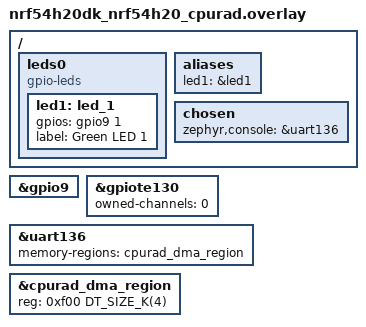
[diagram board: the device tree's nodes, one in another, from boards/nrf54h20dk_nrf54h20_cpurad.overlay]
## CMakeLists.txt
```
#
# Copyright (c) 2024 Nordic Semiconductor
#
# SPDX-License-Identifier: LicenseRef-Nordic-5-Clause
#

cmake_minimum_required(VERSION 3.20.0)
find_package(Zephyr REQUIRED HINTS $ENV{ZEPHYR_BASE})
project(iso_time_sync)

target_include_directories(app PRIVATE include)
target_sources(app PRIVATE src/main.c src/timed_led_toggle.c)

if (CONFIG_BT_CENTRAL)
    target_sources(app PRIVATE src/central.c)
endif()

if (CONFIG_BT_PERIPHERAL)
    target_sources(app PRIVATE src/peripheral.c)
endif()

if (CONFIG_SOC_COMPATIBLE_NRF52X)
    target_sources(app PRIVATE src/controller_time_nrf52.c)
elseif (CONFIG_SOC_COMPATIBLE_NRF5340_CPUAPP)
    target_sources(app PRIVATE src/controller_time_nrf53_app.c)
elseif (CONFIG_SOC_SERIES_NRF54LX)
    target_sources(app PRIVATE src/controller_time_nrf54l.c)
elseif (CONFIG_SOC_SERIES_NRF54HX)
    target_sources(app PRIVATE src/controller_time_nrf54h.c)
else()
    MESSAGE(FATAL_ERROR "Unsupported series")
endif()
```

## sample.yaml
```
sample:
  description: Bluetooth Connection time synchronization sample
  name: Bluetooth Connection time synchronization
tests:
  sample.bluetooth.conn_time_sync:
    sysbuild: true
    build_only: true
    integration_platforms:
      - nrf52840dk/nrf52840
      - nrf52833dk/nrf52833
      - nrf5340dk/nrf5340/cpuapp
      - nrf54l15dk/nrf54l15/cpuapp
      - nrf54l15pdk/nrf54l15/cpuapp
      - nrf54h20dk/nrf54h20/cpuapp
      - nrf54h20dk/nrf54h20/cpurad
    platform_allow:
      - nrf52840dk/nrf52840
      - nrf52833dk/nrf52833
      - nrf5340dk/nrf5340/cpuapp
      - nrf54l15dk/nrf54l15/cpuapp
      - nrf54l15pdk/nrf54l15/cpuapp
      - nrf54h20dk/nrf54h20/cpuapp
      - nrf54h20dk/nrf54h20/cpurad
    tags: bluetooth ci_build sysbuild
```

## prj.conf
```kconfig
#
# Copyright (c) 2024 Nordic Semiconductor
#
# SPDX-License-Identifier: LicenseRef-Nordic-5-Clause
#

CONFIG_NCS_SAMPLES_DEFAULTS=y

CONFIG_BT_DEVICE_NAME="Conn time sync"
CONFIG_BT=y
CONFIG_BT_PERIPHERAL=y
CONFIG_BT_CENTRAL=y
CONFIG_BT_MAX_CONN=3
CONFIG_BT_CTLR_SDC_PERIPHERAL_COUNT=1

CONFIG_BT_GATT_CLIENT=y

CONFIG_CONSOLE=y
CONFIG_CONSOLE_SUBSYS=y
CONFIG_CONSOLE_HANDLER=y
CONFIG_CONSOLE_GETCHAR=y

CONFIG_BT_CTLR_SDC_CONN_ANCHOR_POINT_REPORT=y
CONFIG_BT_HCI_VS_EVT_USER=y
# CONFIG_NRF_REGTOOL_VERBOSITY=3
```

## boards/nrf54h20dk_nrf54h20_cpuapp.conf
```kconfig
CONFIG_GPIO=y
CONFIG_NRFX_DPPI=y
CONFIG_BT_RX_STACK_SIZE=2048
```

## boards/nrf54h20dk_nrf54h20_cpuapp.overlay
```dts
/*
 * Copyright (c) 2023 Nordic Semiconductor ASA
 *
 * SPDX-License-Identifier: LicenseRef-Nordic-5-Clause
 */

 //overlay stuff needs to get fixed first!
    &{/leds/led_1} {
	label = "led1a";  // Keeping the original as is
    };

//     &{/leds0/led_1} {
// 	label = "led1a";  // Renaming to a unique identifier
//     };

 / {
	leds0 {
	    compatible = "gpio-leds";
	    led1: led_1 {
		gpios = <&gpio9 1 GPIO_ACTIVE_HIGH>;
		label = "Green LED 1";
	    };
	};

	aliases {
	    led1 = &led1;
	};

	chosen {
	    zephyr,console = &uart136;
	};
    };

    &gpio9 {
	status = "okay";
    };

    &gpiote130 {
	owned-channels = <0>;
	status = "okay";
    };

// // temp fix to compile for radio core:
//     &uart136 {
// 	status = "okay";
// 	memory-regions = <&cpurad_dma_region>;
//     };

//     &cpuapp_dma_region {
// 	    reg = <0xe80 0x80>;
//     };

//     &cpurad_dma_region {
// 	reg = <0xf00 DT_SIZE_K(4)>;
//     };

//     DPPIC020 for the Radio Core and DPPIC030 for peripheral interactions
//     &dppic020 {
// 	status = "okay";
// 	// source-channels = < 0 1 >;
// 	// sink-channels = < 2 3 >;
// 	source-channels = <0 1 2 3 4 5>;
// 	sink-channels = <6 7 8 9 10 11>;
//     };
```

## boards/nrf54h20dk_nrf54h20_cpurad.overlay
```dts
/*
 * Copyright (c) 2023 Nordic Semiconductor ASA
 *
 * SPDX-License-Identifier: LicenseRef-Nordic-5-Clause
 */

 / {
	leds0 {
	    compatible = "gpio-leds";
	    led1: led_1 {
		gpios = <&gpio9 1 GPIO_ACTIVE_HIGH>;
		label = "Green LED 1";
	    };
	};

	aliases {
	    led1 = &led1;
	};

	chosen {
	    zephyr,console = &uart136;
	};
    };

    &gpio9 {
	status = "okay";
    };

    &gpiote130 {
	owned-channels = <0>;
	status = "okay";
    };

// temp fix to compile for radio core:
    &uart136 {
	status = "okay";
	memory-regions = <&cpurad_dma_region>;
    };

    &cpurad_dma_region {
	reg = <0xf00 DT_SIZE_K(4)>;
    };
```

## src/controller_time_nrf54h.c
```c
/*
 * Copyright (c) 2024 Nordic Semiconductor ASA
 *
 * SPDX-License-Identifier: LicenseRef-Nordic-5-Clause
 */

/** This file implements controller time management for 54 Series devices
 */

#include <zephyr/kernel.h>
#include <nrfx_grtc.h>
#include "conn_time_sync.h"

static uint8_t grtc_channel;

int controller_time_init(void)
{
	int ret;

	ret = nrfx_grtc_channel_alloc(&grtc_channel);
	if (ret != NRFX_SUCCESS) {
		printk("Failed allocating GRTC channel (ret: %d)\n", ret - NRFX_ERROR_BASE_NUM);
		return -ENODEV;
	}

	nrf_grtc_sys_counter_compare_event_enable(NRF_GRTC, grtc_channel);

	return 0;
}

uint64_t controller_time_us_get(void)
{
	int ret;
	uint64_t current_time_us;

	ret = nrfx_grtc_syscounter_get(&current_time_us);
	if (ret != NRFX_SUCCESS) {
		printk("Failed obtaining system time (ret: %d)\n", ret - NRFX_ERROR_BASE_NUM);
		return 0;
	}

	return current_time_us;
}

void controller_time_trigger_set(uint64_t timestamp_us)
{
	int ret;

	nrfx_grtc_channel_t chan_data = {
		.channel = grtc_channel,
	};

	ret = nrfx_grtc_syscounter_cc_absolute_set(&chan_data, timestamp_us, false);
	if (ret != NRFX_SUCCESS) {
		printk("Failed setting CC (ret: %d)\n", ret - NRFX_ERROR_BASE_NUM);
	}
}

uint32_t controller_time_trigger_event_addr_get(void)
{
	return nrf_grtc_event_address_get(NRF_GRTC,
					  nrf_grtc_sys_counter_compare_event_get(grtc_channel));
}

SYS_INIT(controller_time_init, POST_KERNEL, CONFIG_KERNEL_INIT_PRIORITY_DEFAULT);
```

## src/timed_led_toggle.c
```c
/*
 * Copyright (c) 2024 Nordic Semiconductor ASA
 *
 * SPDX-License-Identifier: LicenseRef-Nordic-5-Clause
 */

/** This file implements timed toggling a LED
 *
 * To achieve accurate toggling, it interacts with the controller
 * clock using PPI.
 */

#include <zephyr/kernel.h>
#include <zephyr/device.h>
#include <zephyr/drivers/gpio.h>
#include <soc.h>
#include <hal/nrf_rtc.h>
#include <nrfx_gpiote.h>
#include <helpers/nrfx_gppi.h>
#include "conn_time_sync.h"

#define GPIOTE_INST NRF_DT_GPIOTE_INST(DT_ALIAS(led1), gpios)
#define GPIOTE_NODE DT_NODELABEL(_CONCAT(gpiote, GPIOTE_INST))

BUILD_ASSERT(IS_ENABLED(_CONCAT(CONFIG_, _CONCAT(NRFX_GPIOTE, GPIOTE_INST))),
	     "NRFX_GPIOTE" STRINGIFY(GPIOTE_INST) " must be enabled in Kconfig");

static const nrfx_gpiote_t gpiote = NRFX_GPIOTE_INSTANCE(GPIOTE_INST);
static struct gpio_dt_spec led = GPIO_DT_SPEC_GET_OR(DT_ALIAS(led1), gpios, {0});

static uint8_t previous_led_value;

struct gpio_nrfx_cfg {
	/* gpio_driver_config needs to be first */
	struct gpio_driver_config common;
	NRF_GPIO_Type *port;
	uint32_t edge_sense;
	uint8_t port_num;
	nrfx_gpiote_t gpiote;
};

int timed_led_toggle_init(void)
{
	int err;
	uint8_t ppi_chan_led_toggle;
	uint8_t gpiote_chan_led_toggle;

	const nrfx_gpiote_output_config_t gpiote_output_cfg = NRFX_GPIOTE_DEFAULT_OUTPUT_CONFIG;
	err = gpio_pin_configure_dt(&led, GPIO_OUTPUT_INACTIVE);
	if (err != 0) {
		printk("Error %d: failed to configure LED device %s pin %d\n", err, led.port->name,
		       led.pin);
		return err;
	}
	const struct gpio_nrfx_cfg *cfg = led.port->config;
	nrfx_gpiote_pin_t abs_led_pin = NRF_GPIO_PIN_MAP(cfg->port_num, led.pin);
	// other ways I tried but have more issues needing to import and include more stuff:
	// nrfx_gpiote_pin_t abs_led_pin = NRF_PIN_PORT_TO_PIN_NUMBER(led.pin, led.port);
	// nrfx_gpiote_pin_t abs_led_pin = DT_INST_PROP(0, req_pin);
	// nrfx_gpiote_pin_t abs_led_pin = 289;

	if (nrfx_gpiote_channel_alloc(&gpiote, &gpiote_chan_led_toggle) != NRFX_SUCCESS) {
		printk("Failed allocating GPIOTE chan for setting led\n");
		return -ENOMEM;
	}
#if defined(CONFIG_SOC_SERIES_NRF54HX)
	led.dt_flags = GPIO_ACTIVE_HIGH; // workaround, because default is not set/not set correctly
#endif

	const nrfx_gpiote_task_config_t task_cfg_led_toggle = {
		.task_ch = gpiote_chan_led_toggle,
		.polarity = NRF_GPIOTE_POLARITY_TOGGLE,
		.init_val = (led.dt_flags & GPIO_ACTIVE_HIGH) ?
			NRF_GPIOTE_INITIAL_VALUE_LOW : NRF_GPIOTE_INITIAL_VALUE_HIGH,
	};

	printk("CONFIGURING LED\n");
	if (nrfx_gpiote_output_configure(&gpiote, abs_led_pin, &gpiote_output_cfg,
					 &task_cfg_led_toggle) != NRFX_SUCCESS) {
		printk("Failed configuring GPIOTE chan for toggling led\n");
		return -ENOMEM;
	}

	if (nrfx_gppi_channel_alloc(&ppi_chan_led_toggle) != NRFX_SUCCESS) {
		printk("Failed allocating PPI chan for toggling led\n");
		return -ENOMEM;
	}

	nrfx_gppi_channel_endpoints_setup(ppi_chan_led_toggle,
					  controller_time_trigger_event_addr_get(),
					  nrfx_gpiote_out_task_address_get(&gpiote, abs_led_pin));

	nrfx_gppi_channels_enable(BIT(ppi_chan_led_toggle));
	nrfx_gpiote_out_task_enable(&gpiote, abs_led_pin);

	return 0;
}

void timed_led_toggle_trigger_at(uint8_t value, uint32_t timestamp_us)
{
	/* First obtain the full 64-bit time. */
	const uint64_t current_time_us = controller_time_us_get();
	const uint64_t current_time_most_significant_word = current_time_us & 0xFFFFFFFF00000000UL;

	uint64_t full_timestamp_us = current_time_most_significant_word | timestamp_us;

	if (timestamp_us < (current_time_us & UINT32_MAX)) {
		/* Trigger time is after UINT32 wrap */
		full_timestamp_us += 0x100000000UL;
	}

	controller_time_trigger_set(full_timestamp_us);

	previous_led_value = value;
}
```
